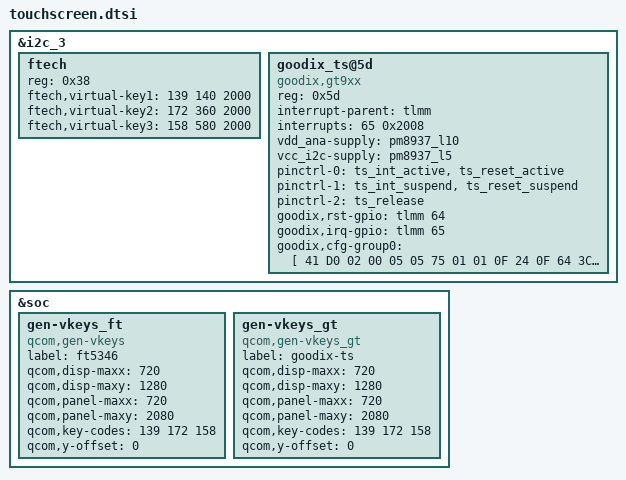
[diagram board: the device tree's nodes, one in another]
/* From stock msm8917-pmi8937-qrd-sku5_S8850?.dtsi */
&i2c_3 { /* BLSP1 QUP3 */
	ftech {
		reg = <0x38>;
		ftech,virtual-key1 = <139 140 2000>;/*menu*/
		ftech,virtual-key2 = <172 360 2000>;/*home*/
		ftech,virtual-key3 = <158 580 2000>;/*back*/
	};
	goodix_ts@5d {
		compatible = "goodix,gt9xx";
		reg = <0x5d>;
		interrupt-parent = <&tlmm>;
		interrupts = <65 0x2008>;
		vdd_ana-supply = <&pm8937_l10>;
		vcc_i2c-supply = <&pm8937_l5>;
		pinctrl-names = "pmx_ts_active","pmx_ts_suspend",
			"pmx_ts_release";
		pinctrl-0 = <&ts_int_active &ts_reset_active>;
		pinctrl-1 = <&ts_int_suspend &ts_reset_suspend>;
		pinctrl-2 = <&ts_release>;
		goodix,rst-gpio = <&tlmm 64 0x00>;
		goodix,irq-gpio = <&tlmm 65 0x2008>;
		goodix,cfg-group0 = [
				41 D0 02 00 05 05 75 01 01 0F 24
				0F 64 3C 03 05 00 00 00 02 00 00
				00 16 19 1C 14 8C 0E 0E 24 00 31
				0D 00 00 00 83 33 1D 00 41 00 00
				00 00 00 08 0A 00 2B 1C 3C 94 D5
				03 08 00 00 04 93 1E 00 82 23 00
				74 29 00 69 2F 00 5F 37 00 5F 20
				40 60 00 F0 40 30 55 50 27 00 00
				00 00 00 00 00 00 00 00 00 00 00
				00 00 00 00 00 00 00 14 19 00 00
				50 50 02 04 06 08 0A 0C 0E 10 12
				14 16 18 1A 1C 00 00 00 00 00 00
				00 00 00 00 00 00 00 00 00 00 1D
				1E 1F 20 21 22 24 26 28 29 2A 1C
				18 16 14 13 12 10 0F 0C 0A 08 06
				04 02 00 00 00 00 00 00 00 00 00
				00 00 00 00 00 00 00 00 9C 01];
	};
};
&soc {
	gen-vkeys_ft {
		/* From stock msm8917-pmi8937-qrd-sku5_S88503.dtsi */
		compatible = "qcom,gen-vkeys";
		label = "ft5346";
		qcom,disp-maxx = <720>;
		qcom,disp-maxy = <1280>;
		qcom,panel-maxx = <720>;
		qcom,panel-maxy = <2080>;
		qcom,key-codes = <139 172 158>;
		qcom,y-offset = <0>;
	};
	gen-vkeys_gt {
		compatible = "qcom,gen-vkeys_gt";
		label = "goodix-ts";
		qcom,disp-maxx = <720>;
		qcom,disp-maxy = <1280>;
		qcom,panel-maxx = <720>;
		qcom,panel-maxy = <2080>;
		qcom,key-codes = <139 172 158>;
		qcom,y-offset = <0>;
	};
};
